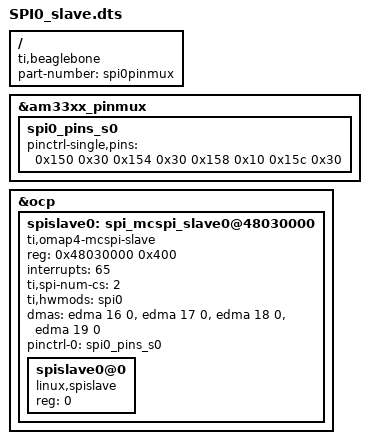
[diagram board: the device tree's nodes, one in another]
/dts-v1/;
/plugin/;

/* SPI0 slave DTS */
/ {

    compatible = "ti,beaglebone", "ti,beaglebone-black";

    part-number = "spi0pinmux";

    fragment@0 {
        target = <&am33xx_pinmux>;
        __overlay__ {
            spi0_pins_s0: spi0_pins_s0 {
                pinctrl-single,pins = <
                  0x150 0x30  /* spi0_sclk, INPUT_PULLUP  | MODE0 */
                  0x154 0x30  /* spi0_d0,   INPUT_PULLUP  | MODE0 */
                  0x158 0x10  /* spi0_d1,   OUTPUT_PULLUP | MODE0 */
                  0x15c 0x30  /* spi0_cs0,  INPUT_PULLUP  | MODE0 */
                >;
            };
        };
    };

    fragment@1 {
        target = <&ocp>;
        __overlay__ {
            #address-cells = <1>;
            #size-cells = <1>;

            spislave0: spi_mcspi_slave0@48030000 {
                compatible = "ti,omap4-mcspi-slave";
                #address-cells = <1>;
                #size-cells = <0>;
                reg = <0x48030000 0x400>;
                interrupts = <65>;
                ti,spi-num-cs = <2>;
                ti,hwmods = "spi0";
                dmas = <&edma 16 0
                        &edma 17 0
                        &edma 18 0
                        &edma 19 0>;
                dma-names = "tx0", "rx0", "tx1", "rx1";
                status = "okay";
                pinctrl-names = "default";
                pinctrl-0 = <&spi0_pins_s0>;
                spislave0@0 {
                    reg = <0>;
                    compatible = "linux,spislave";
                };
            };
        };
    };
};
